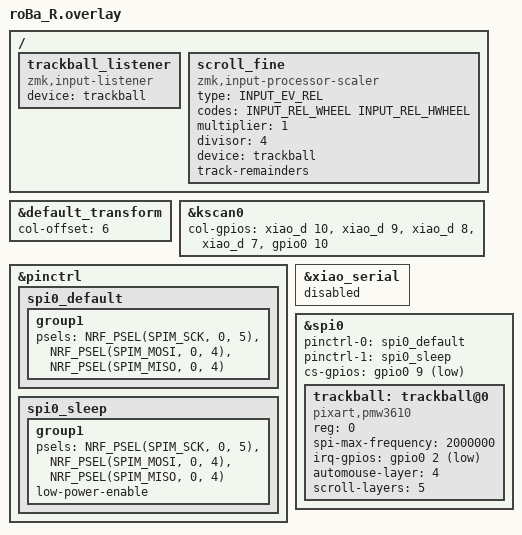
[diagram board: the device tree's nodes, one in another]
#include "roBa.dtsi"

&default_transform {
    col-offset = <6>;
};

&kscan0 {
        col-gpios
            = <&xiao_d 10 GPIO_ACTIVE_HIGH>
            , <&xiao_d 9 GPIO_ACTIVE_HIGH> 
            , <&xiao_d 8 GPIO_ACTIVE_HIGH> 
            , <&xiao_d 7 GPIO_ACTIVE_HIGH> 
            , <&gpio0 10 GPIO_ACTIVE_HIGH>
            ;
};

/ {
    trackball_listener {
        compatible = "zmk,input-listener";
        device = <&trackball>;

    };
};

&pinctrl {
    spi0_default: spi0_default {
        group1 {
            psels = <NRF_PSEL(SPIM_SCK, 0, 5)>,
                <NRF_PSEL(SPIM_MOSI, 0, 4)>,
                <NRF_PSEL(SPIM_MISO, 0, 4)>;
        };
    };

    spi0_sleep: spi0_sleep {
        group1 {
            psels = <NRF_PSEL(SPIM_SCK, 0, 5)>,
                <NRF_PSEL(SPIM_MOSI, 0, 4)>,
                <NRF_PSEL(SPIM_MISO, 0, 4)>;
            low-power-enable;
        };
    };
};

&xiao_serial { status = "disabled"; };

/* ================== ここから追加 ================== */
 / {   /* ルートノードなので & ではなく / で始まります */
    scroll_fine: scroll_fine {
        compatible = "zmk,input-processor-scaler";
        #input-processor-cells = <2>;
        type  = <INPUT_EV_REL>;
        codes = <INPUT_REL_WHEEL INPUT_REL_HWHEEL>;
        multiplier = <1>;      /* 1/4 倍にしたい → 1 */
        divisor    = <4>;      /* もっと細かく → 8 */
        device = <&trackball>;
        track-remainders;      /* 端数を繰り越し、ガタつき防止 */
    };
};
/* ================== ここまで追加 =================== */

&spi0 {
    status = "okay";
    pinctrl-0 = <&spi0_default>;
    pinctrl-1 = <&spi0_sleep>;
    cs-gpios  = <&gpio0 9 GPIO_ACTIVE_LOW>;

    trackball: trackball@0 {
        status = "okay";
        compatible = "pixart,pmw3610";
        reg = <0>;
        spi-max-frequency = <2000000>;
        irq-gpios = <&gpio0 2 (GPIO_ACTIVE_LOW | GPIO_PULL_UP)>;
        automouse-layer = <4>;
        scroll-layers  = <5>;
    };
};


